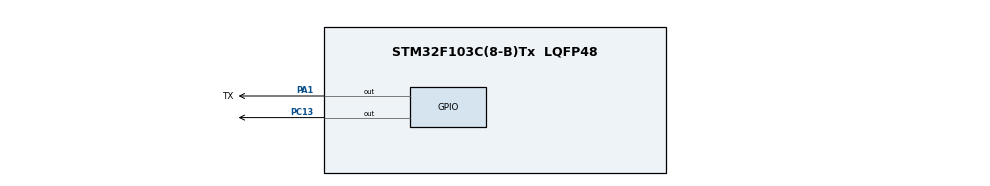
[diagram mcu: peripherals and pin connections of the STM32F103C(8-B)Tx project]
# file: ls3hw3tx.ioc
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Mcu.Family=STM32F1
Mcu.Name=STM32F103C(8-B)Tx
Mcu.Package=LQFP48
NVIC.PriorityGroup=NVIC_PRIORITYGROUP_4
PA1.GPIO_Label=TX
PA1.Signal=GPIO_Output
PA13.Mode=Serial_Wire
PA13.Signal=SYS_JTMS-SWDIO
PA14.Mode=Serial_Wire
PA14.Signal=SYS_JTCK-SWCLK
PC13-TAMPER-RTC.Signal=GPIO_Output
ProjectManager.HeapSize=0x200
ProjectManager.StackSize=0x400
ProjectManager.TargetToolchain=CMake
RCC.APB1Freq_Value=8000000
RCC.APB2Freq_Value=8000000
board=custom

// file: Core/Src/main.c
/* USER CODE BEGIN Header */
/**
  ******************************************************************************
  * @file           : main.c
  * @brief          : Main program body
  ******************************************************************************
  * @attention
  *
  * Copyright (c) 2025 STMicroelectronics.
  * All rights reserved.
  *
  * This software is licensed under terms that can be found in the LICENSE file
  * in the root directory of this software component.
  * If no LICENSE file comes with this software, it is provided AS-IS.
  *
  ******************************************************************************
  */
/* USER CODE END Header */
#include "main.h"
#include "stm32f103xb.h"
#include "stm32f1xx_hal.h"
#include "stm32f1xx_hal_gpio.h"
#include <sys/_intsup.h>

void SystemClock_Config(void);
static void MX_GPIO_Init(void);

/* USER CODE BEGIN 0 */
void Delay_us(uint32_t us)
{
    if (us < 1000) {
        // 对于较短的延时，使用循环计数
        volatile uint32_t count = us * (SystemCoreClock / 1000000) / 5;
        while (count--) {
            __NOP();
        }
    } else {
        // 对于较长的延时，使用HAL_Delay
        HAL_Delay(us / 1000);
        // 处理剩余的微秒部分
        volatile uint32_t count = (us % 1000) * (SystemCoreClock / 1000000) / 5;
        while (count--) {
            __NOP();
        }
    }
}
void SoftUART_Tx(uint8_t data)
{
    uint32_t bit_time = 104; // 微秒，9600 波特率
    uint8_t last_state = 0;  // 记录上一位的状态

    // 起始位
    HAL_GPIO_WritePin(TX_GPIO_Port, TX_Pin, GPIO_PIN_RESET);
    Delay_us(bit_time);

    // 数据位（LSB first）
    for (int i = 0; i < 8; i++) {
        uint8_t current_bit = (data >> i) & 0x01;
        if (current_bit != last_state) {
            HAL_GPIO_WritePin(TX_GPIO_Port, TX_Pin, current_bit);
            last_state = current_bit;
        }
        Delay_us(bit_time);
    }

    // 停止位
    if (last_state != 1) {  // 停止位始终是1
        HAL_GPIO_WritePin(TX_GPIO_Port, TX_Pin, GPIO_PIN_SET);
    }
    Delay_us(bit_time);
}

/* USER CODE END 0 */

int main(void)
{

  /* MCU Configuration--------------------------------------------------------*/

  /* Reset of all peripherals, Initializes the Flash interface and the Systick. */
  HAL_Init();

  /* Configure the system clock */
  SystemClock_Config();

  /* Initialize all configured peripherals */
  MX_GPIO_Init();
  /* USER CODE BEGIN 2 */

 uint8_t value = 0x5A;//数据是90

  /* USER CODE END 2 */

  /* Infinite loop */
  /* USER CODE BEGIN WHILE */
  while (1)
  {
    HAL_GPIO_TogglePin(GPIOC, GPIO_PIN_13);//闪烁表示正常工作
    SoftUART_Tx(value);
    HAL_Delay(1000);
  }
  /* USER CODE END 3 */
}

void SystemClock_Config(void)
{
  RCC_OscInitTypeDef RCC_OscInitStruct = {0};
  RCC_ClkInitTypeDef RCC_ClkInitStruct = {0};

  /** Initializes the RCC Oscillators according to the specified parameters
  * in the RCC_OscInitTypeDef structure.
  */
  RCC_OscInitStruct.OscillatorType = RCC_OSCILLATORTYPE_HSI;
  RCC_OscInitStruct.HSIState = RCC_HSI_ON;
  RCC_OscInitStruct.HSICalibrationValue = RCC_HSICALIBRATION_DEFAULT;
  RCC_OscInitStruct.PLL.PLLState = RCC_PLL_NONE;
  if (HAL_RCC_OscConfig(&RCC_OscInitStruct) != HAL_OK)
  {
    Error_Handler();
  }

  /** Initializes the CPU, AHB and APB buses clocks
  */
  RCC_ClkInitStruct.ClockType = RCC_CLOCKTYPE_HCLK|RCC_CLOCKTYPE_SYSCLK
                              |RCC_CLOCKTYPE_PCLK1|RCC_CLOCKTYPE_PCLK2;
  RCC_ClkInitStruct.SYSCLKSource = RCC_SYSCLKSOURCE_HSI;
  RCC_ClkInitStruct.AHBCLKDivider = RCC_SYSCLK_DIV1;
  RCC_ClkInitStruct.APB1CLKDivider = RCC_HCLK_DIV1;
  RCC_ClkInitStruct.APB2CLKDivider = RCC_HCLK_DIV1;

  if (HAL_RCC_ClockConfig(&RCC_ClkInitStruct, FLASH_LATENCY_0) != HAL_OK)
  {
    Error_Handler();
  }
}

static void MX_GPIO_Init(void)
{
  GPIO_InitTypeDef GPIO_InitStruct = {0};

  /* GPIO Ports Clock Enable */
  __HAL_RCC_GPIOC_CLK_ENABLE();
  __HAL_RCC_GPIOA_CLK_ENABLE();

  /*Configure GPIO pin Output Level */
  HAL_GPIO_WritePin(GPIOC, GPIO_PIN_13, GPIO_PIN_RESET);

  /*Configure GPIO pin Output Level */
  HAL_GPIO_WritePin(GPIOA, GPIO_PIN_1, GPIO_PIN_RESET);

  /*Configure GPIO pin : PC13 */
  GPIO_InitStruct.Pin = GPIO_PIN_13;
  GPIO_InitStruct.Mode = GPIO_MODE_OUTPUT_PP;
  GPIO_InitStruct.Pull = GPIO_NOPULL;
  GPIO_InitStruct.Speed = GPIO_SPEED_FREQ_LOW;
  HAL_GPIO_Init(GPIOC, &GPIO_InitStruct);

  /*Configure GPIO pin : PA1 */
  GPIO_InitStruct.Pin = GPIO_PIN_1;
  GPIO_InitStruct.Mode = GPIO_MODE_OUTPUT_PP;
  GPIO_InitStruct.Pull = GPIO_NOPULL;
  GPIO_InitStruct.Speed = GPIO_SPEED_FREQ_LOW;
  HAL_GPIO_Init(GPIOA, &GPIO_InitStruct);

}

void Error_Handler(void)
{
  __disable_irq();
  while (1)
  {
  }
}
